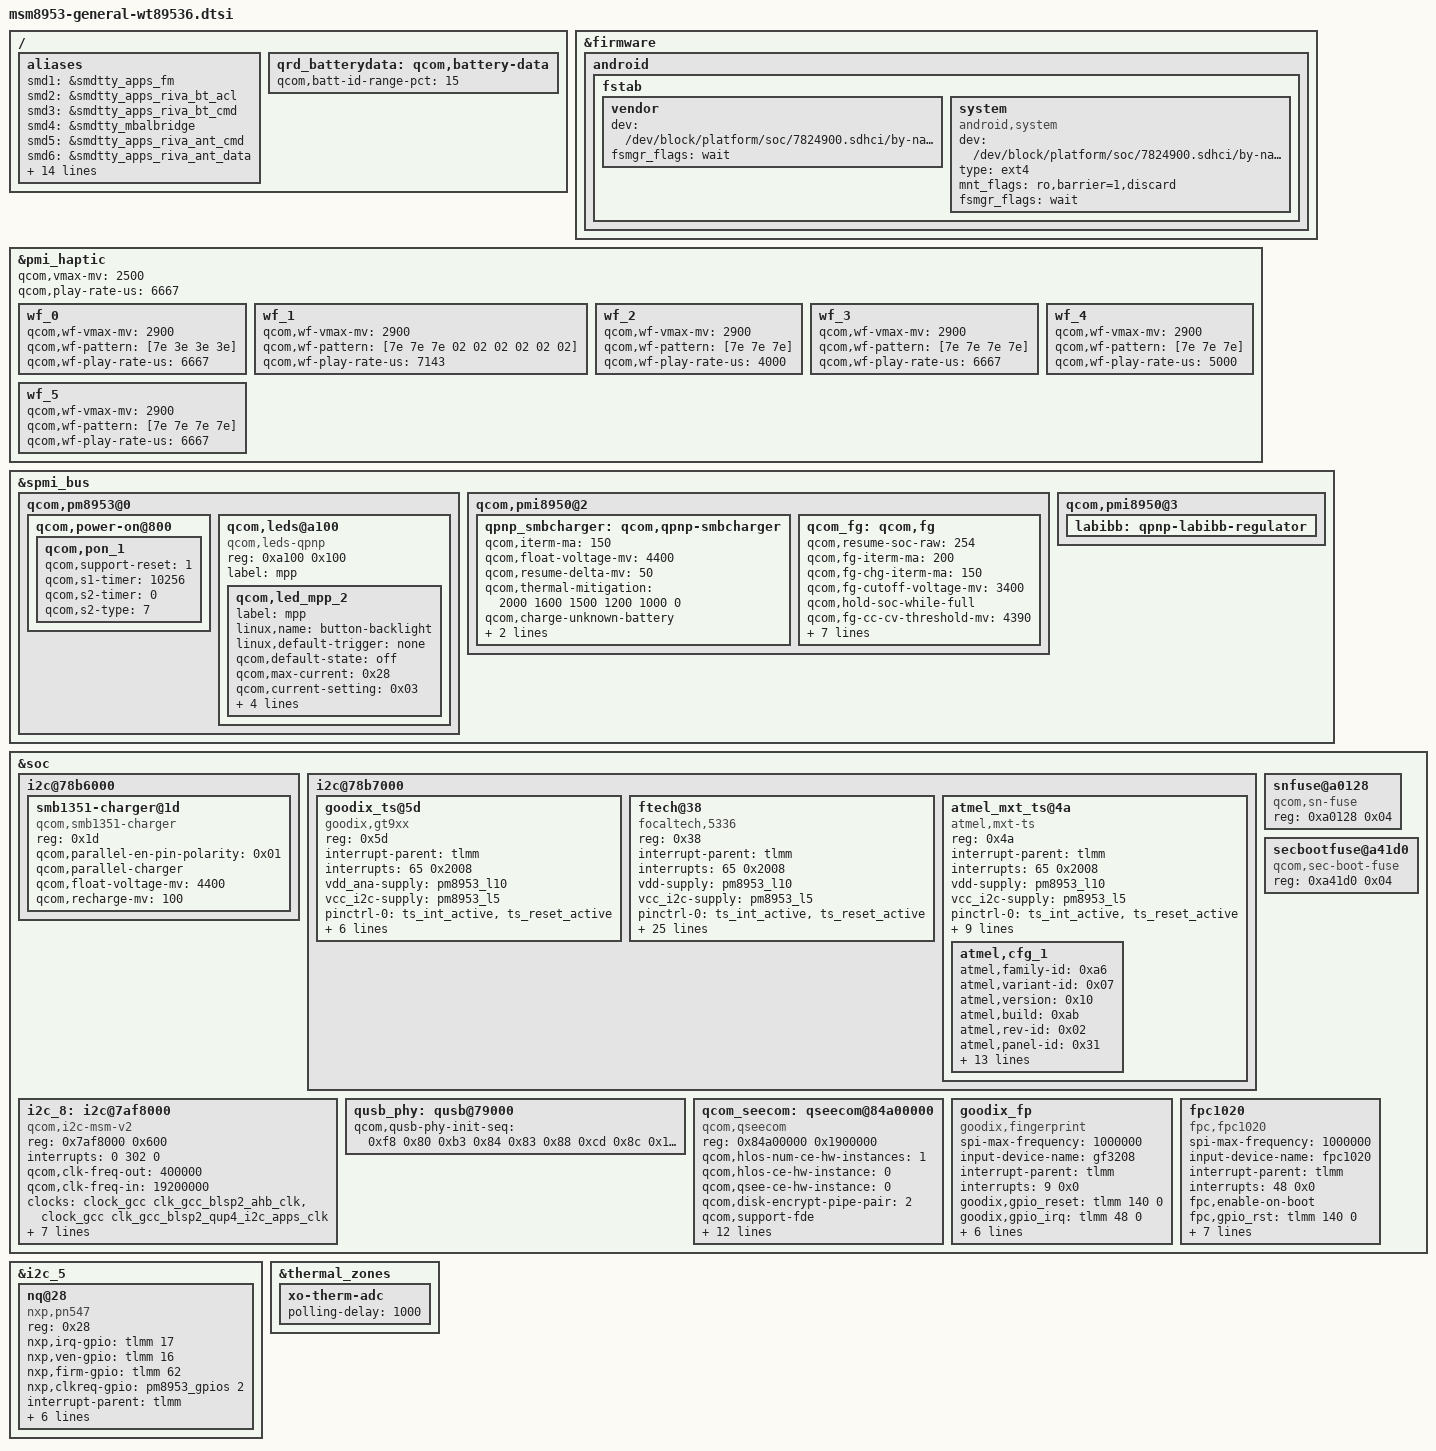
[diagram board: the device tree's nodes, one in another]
/* Copyright (c) 2017, The Linux Foundation. All rights reserved.
 *
 * This program is free software; you can redistribute it and/or modify
 * it under the terms of the GNU General Public License version 2 and
 * only version 2 as published by the Free Software Foundation.
 *
 * This program is distributed in the hope that it will be useful,
 * but WITHOUT ANY WARRANTY; without even the implied warranty of
 * MERCHANTABILITY or FITNESS FOR A PARTICULAR PURPOSE.  See the
 * GNU General Public License for more details.
 */

#include <dt-bindings/pinctrl/qcom,pmic-gpio.h>

/ {
	aliases {
		/* smdtty devices */
		smd1 = &smdtty_apps_fm;
		smd2 = &smdtty_apps_riva_bt_acl;
		smd3 = &smdtty_apps_riva_bt_cmd;
		smd4 = &smdtty_mbalbridge;
		smd5 = &smdtty_apps_riva_ant_cmd;
		smd6 = &smdtty_apps_riva_ant_data;
		smd7 = &smdtty_data1;
		smd8 = &smdtty_data4;
		smd11 = &smdtty_data11;
		smd21 = &smdtty_data21;
		smd36 = &smdtty_loopback;
		sdhc1 = &sdhc_1; /* SDC1 eMMC slot */
		sdhc2 = &sdhc_2; /* SDC2 for SD card */
		i2c1 = &i2c_1;
		i2c2 = &i2c_2;
		i2c3 = &i2c_3;
		i2c5 = &i2c_5;
		//https://www.cnblogs.com/lake-of-embedded-system/p/6182734.html
		i2c8 = &i2c_8;
		spi3 = &spi_3;
		spi6 = &spi_6;
	};
	
	qrd_batterydata: qcom,battery-data {
		qcom,batt-id-range-pct = <15>;

#include "batterydata-2369665_wingtech_b5w_4000mah_averaged_masterslave_apr1st2016.dtsi"
#include "batterydata-Atl_4000mah.dtsi"
#include "batterydata-Drn_3950mah.dtsi"
	};
};

&firmware {
	android {
		/delete-node/ vbmeta;

		fstab {
			vendor {
				dev = "/dev/block/platform/soc/7824900.sdhci/by-name/cust";
				fsmgr_flags = "wait";
			};

			system {
				compatible = "android,system";
				dev = "/dev/block/platform/soc/7824900.sdhci/by-name/system";
				type = "ext4";
				mnt_flags = "ro,barrier=1,discard";
				fsmgr_flags = "wait";
				status = "okay";
			};
		};
	};
};

&pmi_haptic {
	status = "okay";
	qcom,vmax-mv = <2500>;
	qcom,play-rate-us = <6667>;
	
	wf_0 {
		qcom,wf-vmax-mv = <2900>;
		qcom,wf-pattern = [7e 3e 3e 3e];
		qcom,wf-play-rate-us = <6667>;
	};
	
	wf_1 {
		qcom,wf-vmax-mv = <2900>;
		qcom,wf-pattern = [7e 7e 7e 02 02 02 02 02 02];
		qcom,wf-play-rate-us = <7143>;
	};
	
	wf_2 {
		qcom,wf-vmax-mv = <2900>;
		qcom,wf-pattern = [7e 7e 7e];
		qcom,wf-play-rate-us = <4000>;
	};
	
	wf_3 {
		qcom,wf-vmax-mv = <2900>;
		qcom,wf-pattern = [7e 7e 7e 7e];
		qcom,wf-play-rate-us = <6667>;
	};
	
	wf_4 {
		qcom,wf-vmax-mv = <2900>;
		qcom,wf-pattern = [7e 7e 7e];
		qcom,wf-play-rate-us = <5000>;
	};

	wf_5 {
		qcom,wf-vmax-mv = <2900>;
		qcom,wf-pattern = [7e 7e 7e 7e];
		qcom,wf-play-rate-us = <6667>;
	};
};

&spmi_bus {
	qcom,pm8953@0 {
		qcom,power-on@800 {
			qcom,pon_1 {
				qcom,support-reset = <1>;
				qcom,s1-timer = <10256>;
				qcom,s2-timer = <0>;
				qcom,s2-type = <7>;
			};
		};

		/delete-node/ qcom,pm8953_typec@bf00;

		//Button backlight
		qcom,leds@a100 {
			compatible = "qcom,leds-qpnp";
			reg = <0xa100 0x100>;
			label = "mpp";
			status = "ok";

			qcom,led_mpp_2 {
				label = "mpp";
				linux,name = "button-backlight";
				linux,default-trigger = "none";
				qcom,default-state = "off";
				qcom,max-current = <0x28>;
				qcom,current-setting = <0x03>;
				qcom,id = <0x06>;
				qcom,mode = "manual";
				qcom,source-sel = <0x01>;
				qcom,mode-ctrl = <0x60>;
			};
		};
	};

	qcom,pmi8950@2 {
		qpnp_smbcharger: qcom,qpnp-smbcharger {
			qcom,iterm-ma = <150>;
			qcom,float-voltage-mv = <4400>;
			qcom,resume-delta-mv = <50>;
			qcom,thermal-mitigation = <2000 1600 1500 1200 1000 0>;
			qcom,charge-unknown-battery;
			qcom,fastchg-current-comp = <1200>;
			qcom,float-voltage-comp = <15>;
			/delete-property/ qcom,parallel-usb-min-current-ma;
			/delete-property/ qcom,parallel-usb-9v-min-current-ma;
			/delete-property/ qcom,parallel-allowed-lowering-ma;
			/delete-property/ qcom,autoadjust-vfloat;
			/delete-property/ qcom,external-typec;
			/delete-property/ qcom,typec-psy-name;
		};

		qcom_fg: qcom,fg {
			qcom,resume-soc-raw = <254>;
			qcom,fg-iterm-ma = <200>;
			qcom,fg-chg-iterm-ma = <150>;
			qcom,fg-cutoff-voltage-mv = <3400>;
			qcom,hold-soc-while-full;
			qcom,fg-cc-cv-threshold-mv = <4390>;
			qcom,fg-cc-cv-threshold-mv-global = <4370>;
			qcom,fg-vbat-estimate-diff-mv = <200>;
			qcom,fg-restore-batt-info;
			qcom,thermal-coefficients = [da 86 f0 50 08 3c];
			qcom,cold-bat-decidegc = <0>;
			qcom,cool-bat-decidegc = <150>;
			qcom,warm-bat-decidegc = <450>;
			/delete-property/ qcom,resume-soc;
		};
	};

	qcom,pmi8950@3 {
		labibb: qpnp-labibb-regulator {
			status = "okay";
		};
	};
};

&soc {
	//I2C Config
	//i2c2
	i2c@78b6000 { /* BLSP1 QUP2 */
		smb1351-charger@1d {
			compatible = "qcom,smb1351-charger";
			reg = <0x1d>;
			qcom,parallel-en-pin-polarity = <0x01>;
			qcom,parallel-charger;
			qcom,float-voltage-mv = <4400>;
			qcom,recharge-mv = <100>;
		};
	};

	//i2c3	touchscreen
	i2c@78b7000 {
		goodix_ts@5d {
			compatible = "goodix,gt9xx";
			reg = <0x5d>;
			interrupt-parent = <&tlmm>;
			interrupts = <65 0x2008>;
			
			vdd_ana-supply = <&pm8953_l10>;
			vcc_i2c-supply = <&pm8953_l5>;

			pinctrl-names = "pmx_ts_active", "pmx_ts_suspend", "pmx_ts_release";
			pinctrl-0 = <&ts_int_active &ts_reset_active>;
			pinctrl-1 = <&ts_int_suspend &ts_reset_suspend>;
			pinctrl-2 = <&ts_release>;
			
			goodix,rst-gpio = <&tlmm 64 0x00>;
			goodix,irq-gpio = <&tlmm 65 0x2008>;
			goodix,cfg-group0 = [41 d0 02 00 05 05 75 01 01 0f 24 0f 64 3c 03 05 00 00
					     00 02 00 00 00 16 19 1c 14 8c 0e 0e 24 00 31 0d 00 00
					     00 83 33 1d 00 41 00 00 00 00 00 08 0a 00 2b 1c 3c 94
					     d5 03 08 00 00 04 93 1e 00 82 23 00 74 29 00 69 2f 00
					     5f 37 00 5f 20 40 60 00 f0 40 30 55 50 27 00 00 00 00
					     00 00 00 00 00 00 00 00 00 00 00 00 00 00 00 00 14 19
					     00 00 50 50 02 04 06 08 0a 0c 0e 10 12 14 16 18 1a 1c
					     00 00 00 00 00 00 00 00 00 00 00 00 00 00 00 00 1d 1e
					     1f 20 21 22 24 26 28 29 2a 1c 18 16 14 13 12 10 0f 0c
					     0a 08 06 04 02 00 00 00 00 00 00 00 00 00 00 00 00 00
					     00 00 00 00 9c 01];
		};

		ftech@38 {
			compatible = "focaltech,5336";
			reg = <0x38>;
			interrupt-parent = <&tlmm>;
			interrupts = <65 0x2008>;
			vdd-supply = <&pm8953_l10>;
			vcc_i2c-supply = <&pm8953_l5>;
			pinctrl-names = "pmx_ts_active", "pmx_ts_suspend", "pmx_ts_release";
			pinctrl-0 = <&ts_int_active &ts_reset_active>;
			pinctrl-1 = <&ts_int_suspend &ts_reset_suspend>;
			pinctrl-2 = <&ts_release>;
			ftech,name = "ft5336";
			ftech,family-id = <0x36>;
			
			ftech,reset-gpio = <&tlmm 64 0x00>;
			ftech,irq-gpio = <&tlmm 65 0x2008>;

			ftech,display-coords = <0 0 1080 1920>;
			ftech,panel-coords = <0 0 1080 1920>;
			
			ftech,virtual-key1 = <0x8b 0xb4 0x7d0>;/* menu */
			ftech,virtual-key2 = <0xac 0x21c 0x7d0>;/* home */
			ftech,virtual-key3 = <0x9e 0x384 0x7d0>;/* back */
			
			ftech,no-force-update;
			ftech,i2c-pull-up;
			ftech,group-id = <0x01>;
			ftech,hard-reset-delay-ms = <0x14>;
			ftech,soft-reset-delay-ms = <0xc8>;
			ftech,num-max-touches = <0x0a>;
			ftech,fw-delay-aa-ms = <0x1e>;
			ftech,fw-delay-55-ms = <0x1e>;
			ftech,fw-upgrade-id1 = <0x79>;
			ftech,fw-upgrade-id2 = <0x18>;
			ftech,fw-delay-readid-ms = <0x0a>;
			ftech,fw-delay-era-flsh-ms = <0x7d0>;
			ftech,fw-auto-cal;
			ftech,ignore-id-check;
		};

		atmel_mxt_ts@4a {
			compatible = "atmel,mxt-ts";
			reg = <0x4a>;
			interrupt-parent = <&tlmm>;
			interrupts = <65 0x2008>;
			vdd-supply = <&pm8953_l10>;
			vcc_i2c-supply = <&pm8953_l5>;
			pinctrl-names = "pmx_ts_active", "pmx_ts_suspend", "pmx_ts_release";
			pinctrl-0 = <&ts_int_active &ts_reset_active>;
			pinctrl-1 = <&ts_int_suspend &ts_reset_suspend>;
			pinctrl-2 = <&ts_release>;
			atmel,reset-gpio = <&tlmm 64 0x00>;
			atmel,irq-gpio = <&tlmm 65 0x2008>;

			atmel,mxt-fw-name = "mxt_308u.fw";
			atmel,config-array-size = <0x01>;
			atmel,default-config = <0x00>;
			atmel,irqflags = <0x2008>;
			atmel,vendor-id-byte = [00 03];

			atmel,cfg_1 {
				atmel,family-id = <0xa6>;
				atmel,variant-id = <0x07>;
				atmel,version = <0x10>;
				atmel,build = <0xab>;
				atmel,rev-id = <0x02>;
				atmel,panel-id = <0x31>;
				atmel,mxt-cfg-name = "mxt_308u_b5_f.raw";
				atmel,vendor-id = [31 31];
				atmel,key-codes = <0x8b 0xac 0x9e>;//menu home back
				atmel,selfintthr-stylus = <0x00>;
				atmel,t71-tchthr-pos = <0x16>;
				atmel,self-chgtime-min = <0x00>;
				atmel,self-chgtime-max = <0x00>;
				atmel,mult-intthr-sensitive = <0x0c>;
				atmel,mult-intthr-not-sensitive = <0x11>;
				atmel,atchthr-sensitive = <0x06>;
				atmel,mult-tchthr-sensitive = <0x00>;
				atmel,mult-tchthr-not-sensitive = <0x00>;
				atmel,wake-up-self-adcx = <0x10>;
			};
		};
	};

	//Bring I2C8 back
	i2c_8: i2c@7af8000 { /* BLSP2 QUP3 */
		compatible = "qcom,i2c-msm-v2";
		#address-cells = <1>;
		#size-cells = <0>;
		reg-names = "qup_phys_addr";
		reg = <0x7af8000 0x600>;
		interrupt-names = "qup_irq";
		interrupts = <0 302 0>;
		qcom,clk-freq-out = <400000>;
		qcom,clk-freq-in = <19200000>;
		clock-names = "iface_clk", "core_clk";
		clocks = <&clock_gcc clk_gcc_blsp2_ahb_clk>,
			 <&clock_gcc clk_gcc_blsp2_qup4_i2c_apps_clk>;

		pinctrl-names = "i2c_active", "i2c_sleep";
		pinctrl-0 = <&i2c_8_active>;
		pinctrl-1 = <&i2c_8_sleep>;
		qcom,noise-rjct-scl = <0>;
		qcom,noise-rjct-sda = <0>;
		qcom,master-id = <84>;
		dmas = <&dma_blsp1 10 64 0x20000020 0x20>,
		       <&dma_blsp1 11 32 0x20000020 0x20>;
		dma-names = "tx", "rx";
		status = "okay";
	};	
	
	/delete-node/ qseecom@85b00000;

	qusb_phy: qusb@79000 {
		qcom,qusb-phy-init-seq = <0xf8 0x80 0xb3 0x84 0x83 0x88 0xcd 0x8c 0x14 0x9c 0x30
					  0x08 0x79 0x0c 0x21 0x10 0x00 0x90 0x9f 0x1c 0x00 0x18>;
	};

	snfuse@a0128 {
		compatible = "qcom,sn-fuse";
		reg = <0xa0128 0x04>;
		reg-names = "sn-base";
	};

	secbootfuse@a41d0 {
		compatible = "qcom,sec-boot-fuse";
		reg = <0xa41d0 0x04>;
		reg-names = "sec-boot-base";
	};

	qcom_seecom: qseecom@84a00000 { /* renamed from caf qseecom@85b00000 */
		compatible = "qcom,qseecom";
		reg = <0x84a00000 0x1900000>; /* changed by xiaomi */
		reg-names = "secapp-region";
		qcom,hlos-num-ce-hw-instances = <1>;
		qcom,hlos-ce-hw-instance = <0>;
		qcom,qsee-ce-hw-instance = <0>;
		qcom,disk-encrypt-pipe-pair = <2>;
		qcom,support-fde;
		qcom,msm-bus,name = "qseecom-noc";
		qcom,msm-bus,num-cases = <4>;
		qcom,msm-bus,num-paths = <1>;
		qcom,support-bus-scaling;
		qcom,appsbl-qseecom-support;
		qcom,msm-bus,vectors-KBps = <0x37 0x200 0x00 0x00 0x37 0x200 0x00 0x00 0x37 0x200
					     0x1d4c0 0x124f80 0x37 0x200 0x60180 0x3c0f00>;

		clocks = <&clock_gcc clk_crypto_clk_src>,
			 <&clock_gcc clk_gcc_crypto_clk>,
			 <&clock_gcc clk_gcc_crypto_ahb_clk>,
			 <&clock_gcc clk_gcc_crypto_axi_clk>;
		clock-names = "core_clk_src", "core_clk",
			      "iface_clk", "bus_clk";
		qcom,ce-opp-freq = <100000000>;
	};

	//fingerprint
	goodix_fp {
		compatible = "goodix,fingerprint";
		spi-max-frequency = <1000000>;
		input-device-name = "gf3208";
		interrupt-parent = <&tlmm>;
		interrupts = <9 0x0>;

		goodix,gpio_reset = <&tlmm 140 0>;
		goodix,gpio_irq = <&tlmm 48 0>;

		clock-names = "iface_clk", "core_clk";
		clocks = <&clock_gcc clk_gcc_blsp1_ahb_clk>,
			 <&clock_gcc clk_gcc_blsp1_qup1_spi_apps_clk>;

		pinctrl-names = "goodixfp_spi_active",
				"goodixfp_reset_reset",
				"goodixfp_reset_active",
				"goodixfp_irq_active";

		pinctrl-0 = <&goodix_spi_active>;
		pinctrl-1 = <&goodix_reset_reset>;
		pinctrl-2 = <&goodix_reset_active>;
		pinctrl-3 = <&goodix_irq_active>;
	};

	fpc1020 {
		compatible = "fpc,fpc1020";
		spi-max-frequency = <1000000>;
		input-device-name = "fpc1020";
		interrupt-parent = <&tlmm>;
		interrupts = <48 0x0>;
		fpc,enable-on-boot;
		
		fpc,gpio_rst = <&tlmm 140 0>;
		fpc,gpio_irq = <&tlmm 48 0>;

		clock-names = "iface_clk", "core_clk";
		clocks = <&clock_gcc clk_gcc_blsp1_ahb_clk>,
			 <&clock_gcc clk_gcc_blsp1_qup1_spi_apps_clk>;

		pinctrl-names = "fpc1020_spi_active",
				"fpc1020_reset_reset",
				"fpc1020_reset_active",
				"fpc1020_irq_active";

		pinctrl-0 = <&fpc_spi_active>;
		pinctrl-1 = <&fpc_reset_reset>;
		pinctrl-2 = <&fpc_reset_active>;
		pinctrl-3 = <&fpc_irq_active>;
	};
};

&i2c_5 {
	nq@28 {
		compatible = "nxp,pn547";
		reg = <0x28>;
		nxp,irq-gpio = <&tlmm 17 0>;
		nxp,ven-gpio = <&tlmm 16 0>;
		nxp,firm-gpio = <&tlmm 62 0>;
		nxp,clkreq-gpio = <&pm8953_gpios 2 0>;
		interrupt-parent = <&tlmm>;
		nxp,clk-src = "BBCLK2";
		interrupts = <17 0>;
		interrupt-names = "nfc_irq";
		pinctrl-names = "nfc_active", "nfc_suspend";
		pinctrl-0 = <&nfc_int_active &nfc_disable_active>;
		pinctrl-1 = <&nfc_int_suspend &nfc_disable_suspend>;
		clocks = <&clock_gcc clk_bb_clk2_pin>;
		clock-names = "ref_clk";
	};
};

&thermal_zones {
	xo-therm-adc {
		polling-delay = <1000>;
	};
};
